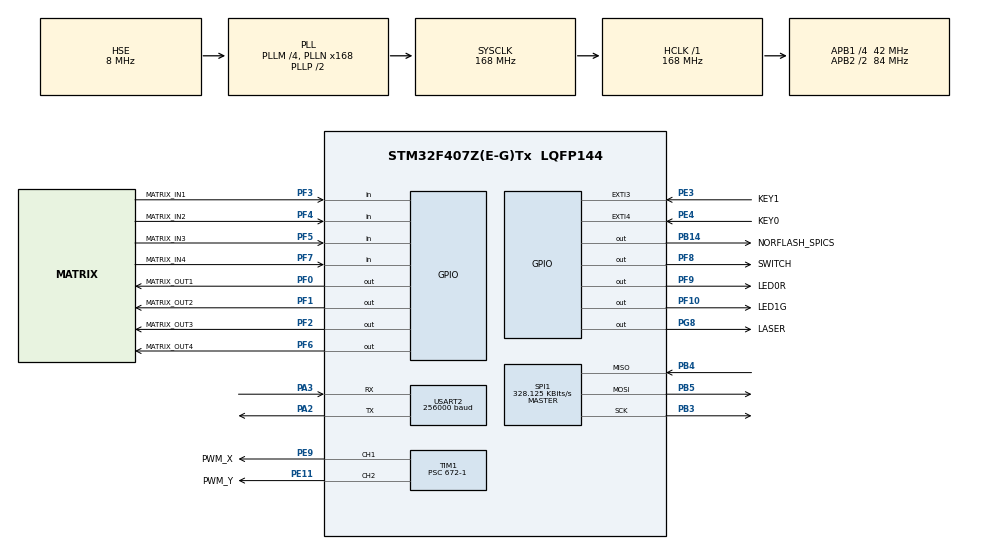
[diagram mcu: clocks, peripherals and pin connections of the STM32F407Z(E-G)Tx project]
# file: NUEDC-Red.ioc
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Dma.Request0=USART2_RX
Dma.USART2_RX.0.Direction=DMA_PERIPH_TO_MEMORY
Dma.USART2_RX.0.FIFOMode=DMA_FIFOMODE_DISABLE
Dma.USART2_RX.0.Instance=DMA1_Stream5
Dma.USART2_RX.0.MemDataAlignment=DMA_MDATAALIGN_BYTE
Dma.USART2_RX.0.MemInc=DMA_MINC_ENABLE
Dma.USART2_RX.0.Mode=DMA_NORMAL
Dma.USART2_RX.0.PeriphDataAlignment=DMA_PDATAALIGN_BYTE
Dma.USART2_RX.0.PeriphInc=DMA_PINC_DISABLE
Dma.USART2_RX.0.Priority=DMA_PRIORITY_VERY_HIGH
FREERTOS.INCLUDE_vTaskDelayUntil=1
FREERTOS.Tasks01=platformTask,3,128,PlatformTask,As weak,NULL,Dynamic,NULL,NULL;pencilTask,2,128,PencilTask,As weak,NULL,Dynamic,NULL,NULL
FREERTOS.configENABLE_FPU=1
FREERTOS.configUSE_NEWLIB_REENTRANT=1
Mcu.Family=STM32F4
Mcu.Name=STM32F407Z(E-G)Tx
Mcu.Package=LQFP144
NVIC.DMA1_Stream5_IRQn=true\:5\:0\:false\:false\:true\:true\:false\:true\:true
NVIC.EXTI3_IRQn=true\:8\:0\:true\:false\:true\:true\:true\:true\:true
NVIC.EXTI4_IRQn=true\:8\:0\:true\:false\:true\:true\:true\:true\:true
NVIC.PriorityGroup=NVIC_PRIORITYGROUP_4
NVIC.TIM1_BRK_TIM9_IRQn=true\:6\:0\:true\:false\:true\:true\:false\:true\:true
NVIC.TIM1_TRG_COM_TIM11_IRQn=true\:15\:0\:false\:false\:true\:false\:false\:true\:true
NVIC.TimeBase=TIM1_TRG_COM_TIM11_IRQn
NVIC.TimeBaseIP=TIM11
PA0-WKUP.Mode=SYS_WakeUp0
PA0-WKUP.Signal=SYS_WKUP
PA13.Mode=Serial_Wire
PA13.Signal=SYS_JTMS-SWDIO
PA14.Mode=Serial_Wire
PA14.Signal=SYS_JTCK-SWCLK
PA2.Mode=Asynchronous
PA2.Signal=USART2_TX
PA3.Mode=Asynchronous
PA3.Signal=USART2_RX
PB14.GPIO_Label=NORFLASH_SPICS
PB14.GPIO_PuPd=GPIO_PULLUP
PB14.GPIO_Speed=GPIO_SPEED_FREQ_VERY_HIGH
PB14.Signal=GPIO_Output
PB3.GPIO_PuPd=GPIO_PULLUP
PB3.Mode=Full_Duplex_Master
PB3.Signal=SPI1_SCK
PB4.GPIO_PuPd=GPIO_PULLUP
PB4.Mode=Full_Duplex_Master
PB4.Signal=SPI1_MISO
PB5.GPIO_PuPd=GPIO_PULLUP
PB5.Mode=Full_Duplex_Master
PB5.Signal=SPI1_MOSI
PE11.GPIO_Label=PWM_Y
PE11.GPIO_Speed=GPIO_SPEED_FREQ_VERY_HIGH
PE11.Signal=S_TIM1_CH2
PE3.GPIO_Label=KEY1
PE3.GPIO_ModeDefaultEXTI=GPIO_MODE_IT_FALLING
PE3.GPIO_PuPd=GPIO_PULLUP
PE3.Signal=GPXTI3
PE4.GPIO_Label=KEY0
PE4.GPIO_ModeDefaultEXTI=GPIO_MODE_IT_FALLING
PE4.GPIO_PuPd=GPIO_PULLUP
PE4.Signal=GPXTI4
PE9.GPIO_Label=PWM_X
PE9.GPIO_Speed=GPIO_SPEED_FREQ_VERY_HIGH
PE9.Signal=S_TIM1_CH1
PF0.GPIO_Label=MATRIX_OUT1
PF0.Signal=GPIO_Output
PF1.GPIO_Label=MATRIX_OUT2
PF1.GPIO_PuPd=GPIO_PULLUP
PF1.Signal=GPIO_Output
PF10.GPIO_Label=LED1G
PF10.GPIO_PuPd=GPIO_PULLUP
PF10.Signal=GPIO_Output
PF2.GPIO_Label=MATRIX_OUT3
PF2.GPIO_PuPd=GPIO_PULLUP
PF2.Signal=GPIO_Output
PF3.GPIO_Label=MATRIX_IN1
PF3.GPIO_PuPd=GPIO_PULLUP
PF3.Signal=GPIO_Input
PF4.GPIO_Label=MATRIX_IN2
PF4.GPIO_PuPd=GPIO_PULLUP
PF4.Signal=GPIO_Input
PF5.GPIO_Label=MATRIX_IN3
PF5.GPIO_PuPd=GPIO_PULLUP
PF5.Signal=GPIO_Input
PF6.GPIO_Label=MATRIX_OUT4
PF6.GPIO_PuPd=GPIO_PULLUP
PF6.Signal=GPIO_Output
PF7.GPIO_Label=MATRIX_IN4
PF7.GPIO_PuPd=GPIO_PULLUP
PF7.Signal=GPIO_Input
PF8.GPIO_Label=SWITCH
PF8.GPIO_PuPd=GPIO_PULLDOWN
PF8.GPIO_Speed=GPIO_SPEED_FREQ_HIGH
PF8.Signal=GPIO_Output
PF9.GPIO_Label=LED0R
PF9.GPIO_PuPd=GPIO_PULLUP
PF9.Signal=GPIO_Output
PG8.GPIO_Label=LASER
PG8.GPIO_PuPd=GPIO_PULLDOWN
PG8.GPIO_Speed=GPIO_SPEED_FREQ_VERY_HIGH
PG8.Signal=GPIO_Output
PH0-OSC_IN.Mode=HSE-External-Oscillator
PH0-OSC_IN.Signal=RCC_OSC_IN
PH1-OSC_OUT.Mode=HSE-External-Oscillator
PH1-OSC_OUT.Signal=RCC_OSC_OUT
ProjectManager.HeapSize=0x200
ProjectManager.StackSize=0x400
ProjectManager.TargetToolchain=STM32CubeIDE
RCC.48MHZClocksFreq_Value=84000000
RCC.AHBFreq_Value=168000000
RCC.APB1CLKDivider=RCC_HCLK_DIV4
RCC.APB1Freq_Value=42000000
RCC.APB1TimFreq_Value=84000000
RCC.APB2CLKDivider=RCC_HCLK_DIV2
RCC.APB2Freq_Value=84000000
RCC.APB2TimFreq_Value=168000000
RCC.CortexFreq_Value=168000000
RCC.HCLKFreq_Value=168000000
RCC.HSE_VALUE=8000000
RCC.HSI_VALUE=16000000
RCC.LSE_VALUE=32768
RCC.PLLM=4
RCC.PLLN=168
RCC.PLLSourceVirtual=RCC_PLLSOURCE_HSE
RCC.SYSCLKFreq_VALUE=168000000
RCC.SYSCLKSource=RCC_SYSCLKSOURCE_PLLCLK
RCC.VCOOutputFreq_Value=336000000
SH.S_TIM1_CH1.0=TIM1_CH1,PWM Generation1 CH1
SH.S_TIM1_CH2.0=TIM1_CH2,PWM Generation2 CH2
SPI1.BaudRatePrescaler=SPI_BAUDRATEPRESCALER_256
SPI1.CLKPhase=SPI_PHASE_2EDGE
SPI1.CLKPolarity=SPI_POLARITY_HIGH
SPI1.CalculateBaudRate=328.125 KBits/s
SPI1.Direction=SPI_DIRECTION_2LINES
SPI1.Mode=SPI_MODE_MASTER
SPI1.VirtualType=VM_MASTER
TIM1.Channel-PWM\ Generation1\ CH1=TIM_CHANNEL_1
TIM1.Channel-PWM\ Generation2\ CH2=TIM_CHANNEL_2
TIM1.Period=833-1
TIM1.Prescaler=672-1
TIM1.Pulse-PWM\ Generation1\ CH1=0
TIM1.Pulse-PWM\ Generation2\ CH2=0
USART2.BaudRate=256000
USART2.VirtualMode=VM_ASYNC
VP_CRC_VS_CRC.Mode=CRC_Activate
VP_FREERTOS_VS_CMSIS_V1.Mode=CMSIS_V1
VP_SYS_VS_tim11.Mode=TIM11
VP_TIM1_VS_ClockSourceINT.Mode=Internal
board=custom

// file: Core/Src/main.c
/* USER CODE BEGIN Header */
/**
  ******************************************************************************
  * @file           : main.c
  * @brief          : Main program body
  ******************************************************************************
  * @attention
  *
  * Copyright (c) 2023 STMicroelectronics.
  * All rights reserved.
  *
  * This software is licensed under terms that can be found in the LICENSE file
  * in the root directory of this software component.
  * If no LICENSE file comes with this software, it is provided AS-IS.
  *
  ******************************************************************************
  */
/* USER CODE END Header */
#include "main.h"
#include "cmsis_os.h"
#include "crc.h"
#include "dma.h"
#include "spi.h"
#include "tim.h"
#include "usart.h"
#include "gpio.h"

/* USER CODE BEGIN Includes */
#include "platformTask.h"
#include "pencilTask.h"
#include "communication.h"
#include "w25qxx.h"
/* USER CODE END Includes */

/* USER CODE BEGIN PV */
extern TIM_HandleTypeDef htim4;
extern uint16_t platformPWMInitVal;
/* USER CODE END PV */

void SystemClock_Config(void);
void MX_FREERTOS_Init(void);

int main(void)
{

  /* MCU Configuration--------------------------------------------------------*/

  /* Reset of all peripherals, Initializes the Flash interface and the Systick. */
  HAL_Init();

  /* Configure the system clock */
  SystemClock_Config();

  /* Initialize all configured peripherals */
  MX_GPIO_Init();
  MX_DMA_Init();
  MX_TIM1_Init();
  MX_CRC_Init();
  MX_SPI1_Init();
  MX_USART2_UART_Init();
  /* USER CODE BEGIN 2 */
  Platform_PWM_Init(platformPWMInitVal);
  USARTCommunicationIT_Init();

  /* USER CODE END 2 */

  /* Call init function for freertos objects (in freertos.c) */
  MX_FREERTOS_Init();

  /* Start scheduler */
  osKernelStart();

  /* We should never get here as control is now taken by the scheduler */
  /* Infinite loop */
  while (1)
  {

  }
}

void SystemClock_Config(void)
{
  RCC_OscInitTypeDef RCC_OscInitStruct = {0};
  RCC_ClkInitTypeDef RCC_ClkInitStruct = {0};

  /** Configure the main internal regulator output voltage
  */
  __HAL_RCC_PWR_CLK_ENABLE();
  __HAL_PWR_VOLTAGESCALING_CONFIG(PWR_REGULATOR_VOLTAGE_SCALE1);

  /** Initializes the RCC Oscillators according to the specified parameters
  * in the RCC_OscInitTypeDef structure.
  */
  RCC_OscInitStruct.OscillatorType = RCC_OSCILLATORTYPE_HSE;
  RCC_OscInitStruct.HSEState = RCC_HSE_ON;
  RCC_OscInitStruct.PLL.PLLState = RCC_PLL_ON;
  RCC_OscInitStruct.PLL.PLLSource = RCC_PLLSOURCE_HSE;
  RCC_OscInitStruct.PLL.PLLM = 4;
  RCC_OscInitStruct.PLL.PLLN = 168;
  RCC_OscInitStruct.PLL.PLLP = RCC_PLLP_DIV2;
  RCC_OscInitStruct.PLL.PLLQ = 4;
  if (HAL_RCC_OscConfig(&RCC_OscInitStruct) != HAL_OK)
  {
    Error_Handler();
  }

  /** Initializes the CPU, AHB and APB buses clocks
  */
  RCC_ClkInitStruct.ClockType = RCC_CLOCKTYPE_HCLK|RCC_CLOCKTYPE_SYSCLK
                              |RCC_CLOCKTYPE_PCLK1|RCC_CLOCKTYPE_PCLK2;
  RCC_ClkInitStruct.SYSCLKSource = RCC_SYSCLKSOURCE_PLLCLK;
  RCC_ClkInitStruct.AHBCLKDivider = RCC_SYSCLK_DIV1;
  RCC_ClkInitStruct.APB1CLKDivider = RCC_HCLK_DIV4;
  RCC_ClkInitStruct.APB2CLKDivider = RCC_HCLK_DIV2;

  if (HAL_RCC_ClockConfig(&RCC_ClkInitStruct, FLASH_LATENCY_5) != HAL_OK)
  {
    Error_Handler();
  }
}

void HAL_TIM_PeriodElapsedCallback(TIM_HandleTypeDef *htim)
{
  if (htim->Instance == TIM11) {
    HAL_IncTick();
  }
}

void Error_Handler(void)
{
  __disable_irq();
  while (1)
  {
  }
}

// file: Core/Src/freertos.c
/* USER CODE BEGIN Header */
/**
  ******************************************************************************
  * File Name          : freertos.c
  * Description        : Code for freertos applications
  ******************************************************************************
  * @attention
  *
  * Copyright (c) 2023 STMicroelectronics.
  * All rights reserved.
  *
  * This software is licensed under terms that can be found in the LICENSE file
  * in the root directory of this software component.
  * If no LICENSE file comes with this software, it is provided AS-IS.
  *
  ******************************************************************************
  */
/* USER CODE END Header */

#include "FreeRTOS.h"
#include "task.h"
#include "main.h"
#include "cmsis_os.h"

osThreadId platformTaskHandle;
osThreadId pencilTaskHandle;

void PlatformTask(void const * argument);
void PencilTask(void const * argument);

void MX_FREERTOS_Init(void); /* (MISRA C 2004 rule 8.1) */

/* GetIdleTaskMemory prototype (linked to static allocation support) */
void vApplicationGetIdleTaskMemory( StaticTask_t **ppxIdleTaskTCBBuffer, StackType_t **ppxIdleTaskStackBuffer, uint32_t *pulIdleTaskStackSize );

/* USER CODE BEGIN GET_IDLE_TASK_MEMORY */
static StaticTask_t xIdleTaskTCBBuffer;
static StackType_t xIdleStack[configMINIMAL_STACK_SIZE];

void vApplicationGetIdleTaskMemory( StaticTask_t **ppxIdleTaskTCBBuffer, StackType_t **ppxIdleTaskStackBuffer, uint32_t *pulIdleTaskStackSize )
{
  *ppxIdleTaskTCBBuffer = &xIdleTaskTCBBuffer;
  *ppxIdleTaskStackBuffer = &xIdleStack[0];
  *pulIdleTaskStackSize = configMINIMAL_STACK_SIZE;
  /* place for user code */
}
/* USER CODE END GET_IDLE_TASK_MEMORY */

void MX_FREERTOS_Init(void) {

  /* Create the thread(s) */
  /* definition and creation of platformTask */
  osThreadDef(platformTask, PlatformTask, osPriorityRealtime, 0, 128);
  platformTaskHandle = osThreadCreate(osThread(platformTask), NULL);

  /* definition and creation of pencilTask */
  osThreadDef(pencilTask, PencilTask, osPriorityHigh, 0, 128);
  pencilTaskHandle = osThreadCreate(osThread(pencilTask), NULL);

}

__weak void PlatformTask(void const * argument)
{
  for(;;)
  {
    osDelay(1);
  }
}

__weak void PencilTask(void const * argument)
{
  for(;;)
  {
    osDelay(1);
  }
}
